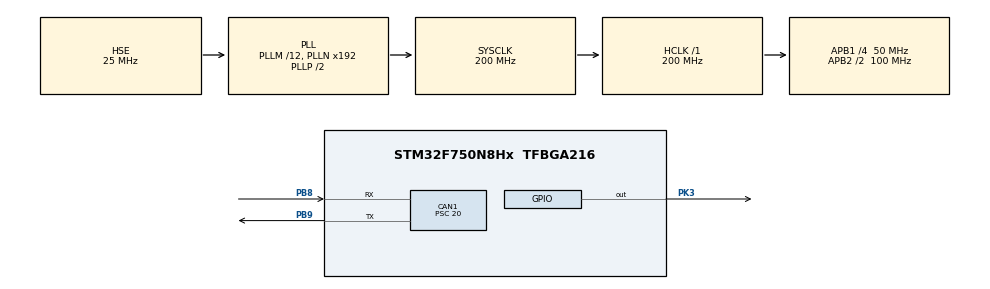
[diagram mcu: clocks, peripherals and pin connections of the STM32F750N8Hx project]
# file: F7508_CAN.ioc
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Mcu.Family=STM32F7
RCC.PLLSourceVirtual=RCC_PLLSOURCE_HSE
PK3.Signal=GPIO_Output
RCC.CortexFreq_Value=200000000
CAN1.CalculateBaudRate=500000
RCC.APB1CLKDivider=RCC_HCLK_DIV4
RCC.PWR_Regulator_Voltage_Scale=PWR_REGULATOR_VOLTAGE_SCALE1
RCC.SYSCLKSource=RCC_SYSCLKSOURCE_PLLCLK
ProjectManager.StackSize=0x400
CAN1.BS2=CAN_BS2_2TQ
CAN1.BS1=CAN_BS1_2TQ
ProjectManager.TargetToolchain=STM32CubeIDE
PH0/OSC_IN.Mode=HSE-External-Oscillator
RCC.HCLKFreq_Value=200000000
RCC.FLatency=FLASH_LATENCY_6
RCC.APB2TimFreq_Value=200000000
PB9.Mode=CAN_Activate
PH1/OSC_OUT.Signal=RCC_OSC_OUT
RCC.USBFreq_Value=200000000
RCC.LSE_VALUE=32768
RCC.AHBFreq_Value=200000000
RCC.HSE_VALUE=25000000
board=STM32F7508-DK
RCC.VCOOutputFreq_Value=400000000
PH0/OSC_IN.Signal=RCC_OSC_IN
RCC.APB2Freq_Value=100000000
PH1/OSC_OUT.Mode=HSE-External-Oscillator
Mcu.Name=STM32F750N8Hx
RCC.SYSCLKFreq_VALUE=200000000
CAN1.Prescaler=20
PB9.Signal=CAN1_TX
Mcu.Package=TFBGA216
ProjectManager.HeapSize=0x200
RCC.HSI_VALUE=16000000
NVIC.PriorityGroup=NVIC_PRIORITYGROUP_4
RCC.APB2CLKDivider=RCC_HCLK_DIV2
RCC.PLLM=12
PB8.Mode=CAN_Activate
RCC.APB1TimFreq_Value=100000000
PB8.Signal=CAN1_RX
RCC.APB1Freq_Value=50000000
CAN1.CalculateTimeBit=2000.00
NVIC.CAN1_RX0_IRQn=true\:0\:0\:false\:false\:true\:true\:true
CAN1.CalculateTimeQuantum=400.0

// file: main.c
/* USER CODE BEGIN Header */
/**
  ******************************************************************************
  * @file           : main.c
  * @brief          : Main program body
  ******************************************************************************
  * @attention
  *
  * <h2><center>&copy; Copyright (c) 2021 STMicroelectronics.
  * All rights reserved.</center></h2>
  *
  * This software component is licensed by ST under BSD 3-Clause license,
  * the "License"; You may not use this file except in compliance with the
  * License. You may obtain a copy of the License at:
  *                        opensource.org/licenses/BSD-3-Clause
  *
  ******************************************************************************
  */
/* USER CODE END Header */
#include "main.h"

/* USER CODE BEGIN Includes */
#include "string.h"
#include "stdio.h"
/* USER CODE END Includes */

CAN_HandleTypeDef hcan1;

void SystemClock_Config(void);
static void MX_GPIO_Init(void);
static void MX_CAN1_Init(void);

/* USER CODE BEGIN 0 */

CAN_HandleTypeDef     CanHandle;
CAN_TxHeaderTypeDef   TxHeader;
CAN_RxHeaderTypeDef   RxHeader;
uint8_t               TxData[8];
uint8_t               RxData[8];
uint32_t              TxMailbox;

int isTransmit = 0;

void HAL_CAN_RxFifo0MsgPendingCallback(CAN_HandleTypeDef *hcan)
{
  if (HAL_CAN_GetRxMessage(hcan, CAN_RX_FIFO0, &RxHeader, RxData) != HAL_OK)
  {
    Error_Handler();
  }

  // additional filter
  if (strncmp((char *)RxData, "F750",RxHeader.DLC) == 0)
  {
	  isTransmit = 1;
  }
}

int indx = 0;

/* USER CODE END 0 */

int main(void)
{

  /* MCU Configuration--------------------------------------------------------*/

  /* Reset of all peripherals, Initializes the Flash interface and the Systick. */
  HAL_Init();

  /* Configure the system clock */
  SystemClock_Config();

  /* Initialize all configured peripherals */
  MX_GPIO_Init();
  MX_CAN1_Init();
  /* USER CODE BEGIN 2 */
  if (HAL_CAN_Start(&hcan1) != HAL_OK)
  {
	  Error_Handler();
  }

  HAL_CAN_ActivateNotification (&hcan1, CAN_IT_RX_FIFO0_MSG_PENDING);

  TxHeader.StdId = 0x215;   // some random ID
  TxHeader.ExtId = 0x00;
  TxHeader.RTR = CAN_RTR_DATA;
  TxHeader.IDE = CAN_ID_STD;
  TxHeader.DLC = 8;
  TxHeader.TransmitGlobalTime = DISABLE;

  /* USER CODE END 2 */

  /* Infinite loop */
  while (1)
  {

	  /* USER CODE BEGIN 3 */

	  if (isTransmit)
	  {
//		  HAL_GPIO_WritePin(GPIOC, GPIO_PIN_13, GPIO_PIN_RESET);
		  sprintf ((char *)TxData, "F750=%2d", indx++);
		  HAL_Delay (750);

		  if (HAL_CAN_AddTxMessage(&hcan1, &TxHeader, TxData, &TxMailbox) != HAL_OK)
		  {
			  Error_Handler ();
		  }

		  isTransmit = 0;

	  }

//	  HAL_GPIO_WritePin(GPIOC, GPIO_PIN_13, GPIO_PIN_SET);
  }
  /* USER CODE END 3 */
}

void SystemClock_Config(void)
{
  RCC_OscInitTypeDef RCC_OscInitStruct = {0};
  RCC_ClkInitTypeDef RCC_ClkInitStruct = {0};

  /** Configure the main internal regulator output voltage
  */
  __HAL_RCC_PWR_CLK_ENABLE();
  __HAL_PWR_VOLTAGESCALING_CONFIG(PWR_REGULATOR_VOLTAGE_SCALE1);
  /** Initializes the RCC Oscillators according to the specified parameters
  * in the RCC_OscInitTypeDef structure.
  */
  RCC_OscInitStruct.OscillatorType = RCC_OSCILLATORTYPE_HSE;
  RCC_OscInitStruct.HSEState = RCC_HSE_ON;
  RCC_OscInitStruct.PLL.PLLState = RCC_PLL_ON;
  RCC_OscInitStruct.PLL.PLLSource = RCC_PLLSOURCE_HSE;
  RCC_OscInitStruct.PLL.PLLM = 12;
  RCC_OscInitStruct.PLL.PLLN = 192;
  RCC_OscInitStruct.PLL.PLLP = RCC_PLLP_DIV2;
  RCC_OscInitStruct.PLL.PLLQ = 2;
  if (HAL_RCC_OscConfig(&RCC_OscInitStruct) != HAL_OK)
  {
    Error_Handler();
  }
  /** Activate the Over-Drive mode
  */
  if (HAL_PWREx_EnableOverDrive() != HAL_OK)
  {
    Error_Handler();
  }
  /** Initializes the CPU, AHB and APB buses clocks
  */
  RCC_ClkInitStruct.ClockType = RCC_CLOCKTYPE_HCLK|RCC_CLOCKTYPE_SYSCLK
                              |RCC_CLOCKTYPE_PCLK1|RCC_CLOCKTYPE_PCLK2;
  RCC_ClkInitStruct.SYSCLKSource = RCC_SYSCLKSOURCE_PLLCLK;
  RCC_ClkInitStruct.AHBCLKDivider = RCC_SYSCLK_DIV1;
  RCC_ClkInitStruct.APB1CLKDivider = RCC_HCLK_DIV4;
  RCC_ClkInitStruct.APB2CLKDivider = RCC_HCLK_DIV2;

  if (HAL_RCC_ClockConfig(&RCC_ClkInitStruct, FLASH_LATENCY_6) != HAL_OK)
  {
    Error_Handler();
  }
}

static void MX_CAN1_Init(void)
{

  hcan1.Instance = CAN1;
  hcan1.Init.Prescaler = 20;
  hcan1.Init.Mode = CAN_MODE_NORMAL;
  hcan1.Init.SyncJumpWidth = CAN_SJW_1TQ;
  hcan1.Init.TimeSeg1 = CAN_BS1_2TQ;
  hcan1.Init.TimeSeg2 = CAN_BS2_2TQ;
  hcan1.Init.TimeTriggeredMode = DISABLE;
  hcan1.Init.AutoBusOff = DISABLE;
  hcan1.Init.AutoWakeUp = DISABLE;
  hcan1.Init.AutoRetransmission = DISABLE;
  hcan1.Init.ReceiveFifoLocked = DISABLE;
  hcan1.Init.TransmitFifoPriority = DISABLE;
  if (HAL_CAN_Init(&hcan1) != HAL_OK)
  {
    Error_Handler();
  }
  /* USER CODE BEGIN CAN1_Init 2 */

  CAN_FilterTypeDef canfilterconfig;

  canfilterconfig.FilterActivation = CAN_FILTER_ENABLE;
  canfilterconfig.FilterBank = 20;
  canfilterconfig.FilterFIFOAssignment = CAN_RX_FIFO0;
  canfilterconfig.FilterIdHigh = 0x446<<5;
  canfilterconfig.FilterIdLow = 0x0000;
  canfilterconfig.FilterMaskIdHigh = 0x446<<5;
  canfilterconfig.FilterMaskIdLow = 0x0000;
  canfilterconfig.FilterMode = CAN_FILTERMODE_IDMASK;
  canfilterconfig.FilterScale = CAN_FILTERSCALE_32BIT;
  canfilterconfig.SlaveStartFilterBank = 30;

  HAL_CAN_ConfigFilter(&hcan1, &canfilterconfig);

  /* USER CODE END CAN1_Init 2 */

}

static void MX_GPIO_Init(void)
{
  GPIO_InitTypeDef GPIO_InitStruct = {0};

  /* GPIO Ports Clock Enable */
  __HAL_RCC_GPIOB_CLK_ENABLE();
  __HAL_RCC_GPIOK_CLK_ENABLE();
  __HAL_RCC_GPIOH_CLK_ENABLE();

  /*Configure GPIO pin Output Level */
  HAL_GPIO_WritePin(GPIOK, GPIO_PIN_3, GPIO_PIN_RESET);

  /*Configure GPIO pin : PK3 */
  GPIO_InitStruct.Pin = GPIO_PIN_3;
  GPIO_InitStruct.Mode = GPIO_MODE_OUTPUT_PP;
  GPIO_InitStruct.Pull = GPIO_NOPULL;
  GPIO_InitStruct.Speed = GPIO_SPEED_FREQ_LOW;
  HAL_GPIO_Init(GPIOK, &GPIO_InitStruct);

}

void Error_Handler(void)
{
  __disable_irq();
  while (1)
  {
  }
}

/************************ (C) COPYRIGHT STMicroelectronics *****END OF FILE****/
